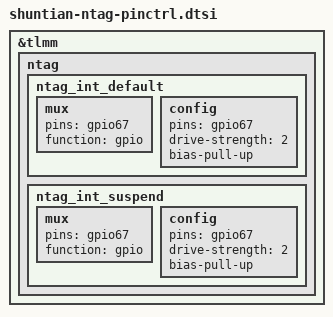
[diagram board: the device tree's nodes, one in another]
/*for shuntian-ntag pinctrl */
&tlmm {
	ntag {
		ntag_int_default: ntag_int_default {
			mux {
				pins = "gpio67";
				function = "gpio";
			};

			config {
				pins = "gpio67";
				drive-strength = <2>; /* 2 MA */
				bias-pull-up;
			};
		};

		ntag_int_suspend: ntag_int_suspend {
			mux {
				pins = "gpio67";
				function = "gpio";
			};

			config {
				pins = "gpio67";
				drive-strength = <2>; /* 2 MA */
				bias-pull-up;
			};
		};
	}; //ntag
};
